VERSION ""

NS_ :

BS_:

BU_: XXX

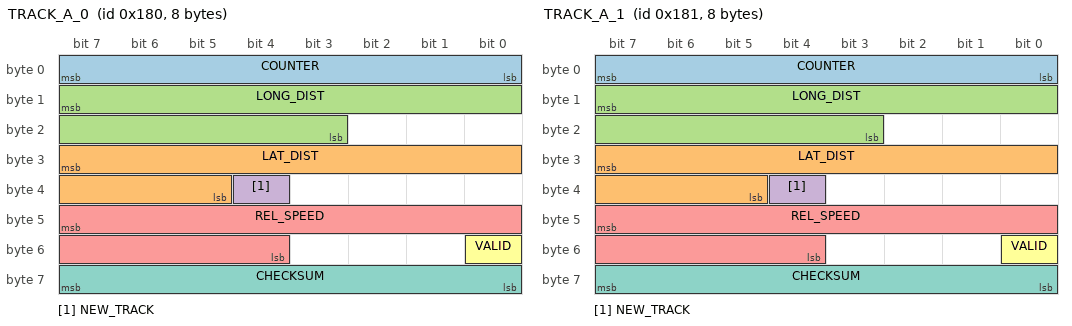
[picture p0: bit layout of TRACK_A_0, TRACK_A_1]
BO_ 384 TRACK_A_0: 8 XXX
 SG_ COUNTER : 7|8@0+ (1,0) [0|255] "" XXX
 SG_ LAT_DIST : 31|11@0- (0.04,0) [-50|50] "m" XXX
 SG_ LONG_DIST : 15|13@0+ (0.04,0) [0|300] "m" XXX
 SG_ NEW_TRACK : 36|1@0+ (1,0) [0|1] "" XXX
 SG_ REL_SPEED : 47|12@0- (0.025,0) [-100|100] "m/s" XXX
 SG_ VALID : 48|1@0+ (1,0) [0|1] "" XXX
 SG_ CHECKSUM : 63|8@0+ (1,0) [0|255] "" XXX

BO_ 385 TRACK_A_1: 8 XXX
 SG_ COUNTER : 7|8@0+ (1,0) [0|255] "" XXX
 SG_ LAT_DIST : 31|11@0- (0.04,0) [-50|50] "m" XXX
 SG_ LONG_DIST : 15|13@0+ (0.04,0) [0|300] "m" XXX
 SG_ NEW_TRACK : 36|1@0+ (1,0) [0|1] "" XXX
 SG_ REL_SPEED : 47|12@0- (0.025,0) [-100|100] "m/s" XXX
 SG_ VALID : 48|1@0+ (1,0) [0|1] "" XXX
 SG_ CHECKSUM : 63|8@0+ (1,0) [0|255] "" XXX

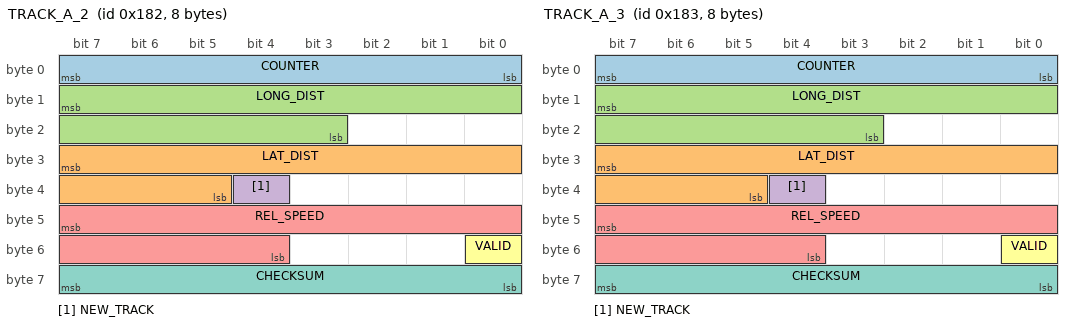
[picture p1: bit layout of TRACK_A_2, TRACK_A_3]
BO_ 386 TRACK_A_2: 8 XXX
 SG_ COUNTER : 7|8@0+ (1,0) [0|255] "" XXX
 SG_ LAT_DIST : 31|11@0- (0.04,0) [-50|50] "m" XXX
 SG_ LONG_DIST : 15|13@0+ (0.04,0) [0|300] "m" XXX
 SG_ NEW_TRACK : 36|1@0+ (1,0) [0|1] "" XXX
 SG_ REL_SPEED : 47|12@0- (0.025,0) [-100|100] "m/s" XXX
 SG_ VALID : 48|1@0+ (1,0) [0|1] "" XXX
 SG_ CHECKSUM : 63|8@0+ (1,0) [0|255] "" XXX

BO_ 387 TRACK_A_3: 8 XXX
 SG_ COUNTER : 7|8@0+ (1,0) [0|255] "" XXX
 SG_ LAT_DIST : 31|11@0- (0.04,0) [-50|50] "m" XXX
 SG_ LONG_DIST : 15|13@0+ (0.04,0) [0|300] "m" XXX
 SG_ NEW_TRACK : 36|1@0+ (1,0) [0|1] "" XXX
 SG_ REL_SPEED : 47|12@0- (0.025,0) [-100|100] "m/s" XXX
 SG_ VALID : 48|1@0+ (1,0) [0|1] "" XXX
 SG_ CHECKSUM : 63|8@0+ (1,0) [0|255] "" XXX

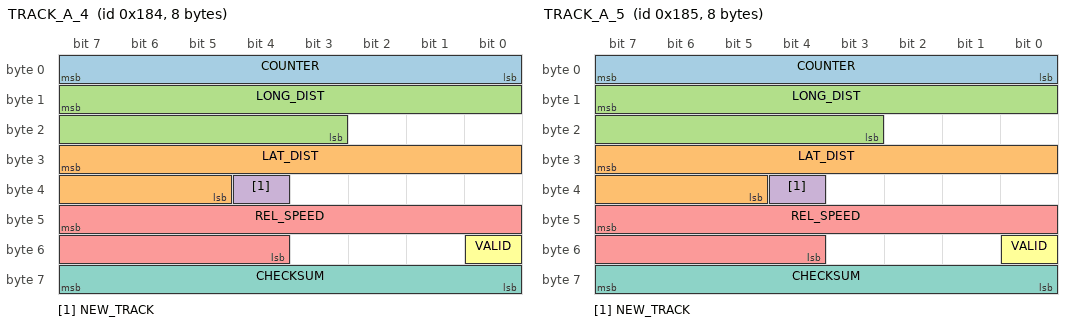
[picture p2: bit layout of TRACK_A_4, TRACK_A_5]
BO_ 388 TRACK_A_4: 8 XXX
 SG_ COUNTER : 7|8@0+ (1,0) [0|255] "" XXX
 SG_ LAT_DIST : 31|11@0- (0.04,0) [-50|50] "m" XXX
 SG_ LONG_DIST : 15|13@0+ (0.04,0) [0|300] "m" XXX
 SG_ NEW_TRACK : 36|1@0+ (1,0) [0|1] "" XXX
 SG_ REL_SPEED : 47|12@0- (0.025,0) [-100|100] "m/s" XXX
 SG_ VALID : 48|1@0+ (1,0) [0|1] "" XXX
 SG_ CHECKSUM : 63|8@0+ (1,0) [0|255] "" XXX

BO_ 389 TRACK_A_5: 8 XXX
 SG_ COUNTER : 7|8@0+ (1,0) [0|255] "" XXX
 SG_ LAT_DIST : 31|11@0- (0.04,0) [-50|50] "m" XXX
 SG_ LONG_DIST : 15|13@0+ (0.04,0) [0|300] "m" XXX
 SG_ NEW_TRACK : 36|1@0+ (1,0) [0|1] "" XXX
 SG_ REL_SPEED : 47|12@0- (0.025,0) [-100|100] "m/s" XXX
 SG_ VALID : 48|1@0+ (1,0) [0|1] "" XXX
 SG_ CHECKSUM : 63|8@0+ (1,0) [0|255] "" XXX

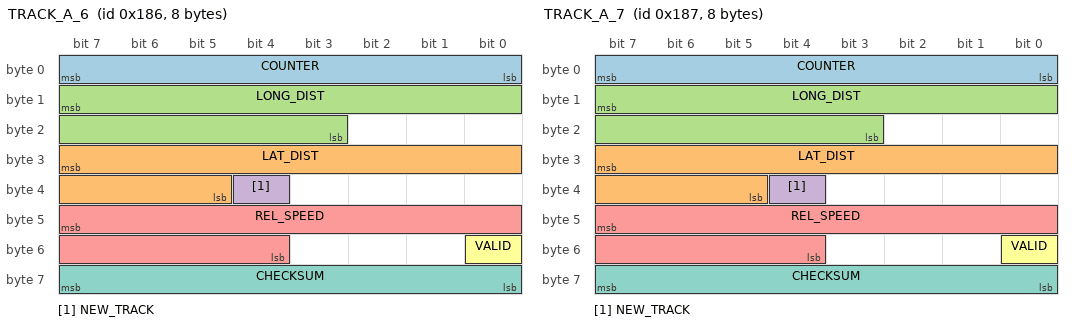
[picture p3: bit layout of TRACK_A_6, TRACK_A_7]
BO_ 390 TRACK_A_6: 8 XXX
 SG_ COUNTER : 7|8@0+ (1,0) [0|255] "" XXX
 SG_ LAT_DIST : 31|11@0- (0.04,0) [-50|50] "m" XXX
 SG_ LONG_DIST : 15|13@0+ (0.04,0) [0|300] "m" XXX
 SG_ NEW_TRACK : 36|1@0+ (1,0) [0|1] "" XXX
 SG_ REL_SPEED : 47|12@0- (0.025,0) [-100|100] "m/s" XXX
 SG_ VALID : 48|1@0+ (1,0) [0|1] "" XXX
 SG_ CHECKSUM : 63|8@0+ (1,0) [0|255] "" XXX

BO_ 391 TRACK_A_7: 8 XXX
 SG_ COUNTER : 7|8@0+ (1,0) [0|255] "" XXX
 SG_ LAT_DIST : 31|11@0- (0.04,0) [-50|50] "m" XXX
 SG_ LONG_DIST : 15|13@0+ (0.04,0) [0|300] "m" XXX
 SG_ NEW_TRACK : 36|1@0+ (1,0) [0|1] "" XXX
 SG_ REL_SPEED : 47|12@0- (0.025,0) [-100|100] "m/s" XXX
 SG_ VALID : 48|1@0+ (1,0) [0|1] "" XXX
 SG_ CHECKSUM : 63|8@0+ (1,0) [0|255] "" XXX

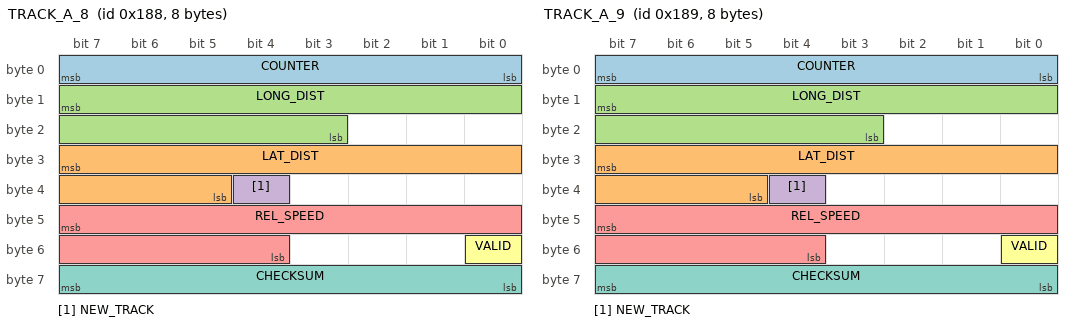
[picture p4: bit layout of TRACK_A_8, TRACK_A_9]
BO_ 392 TRACK_A_8: 8 XXX
 SG_ COUNTER : 7|8@0+ (1,0) [0|255] "" XXX
 SG_ LAT_DIST : 31|11@0- (0.04,0) [-50|50] "m" XXX
 SG_ LONG_DIST : 15|13@0+ (0.04,0) [0|300] "m" XXX
 SG_ NEW_TRACK : 36|1@0+ (1,0) [0|1] "" XXX
 SG_ REL_SPEED : 47|12@0- (0.025,0) [-100|100] "m/s" XXX
 SG_ VALID : 48|1@0+ (1,0) [0|1] "" XXX
 SG_ CHECKSUM : 63|8@0+ (1,0) [0|255] "" XXX

BO_ 393 TRACK_A_9: 8 XXX
 SG_ COUNTER : 7|8@0+ (1,0) [0|255] "" XXX
 SG_ LAT_DIST : 31|11@0- (0.04,0) [-50|50] "m" XXX
 SG_ LONG_DIST : 15|13@0+ (0.04,0) [0|300] "m" XXX
 SG_ NEW_TRACK : 36|1@0+ (1,0) [0|1] "" XXX
 SG_ REL_SPEED : 47|12@0- (0.025,0) [-100|100] "m/s" XXX
 SG_ VALID : 48|1@0+ (1,0) [0|1] "" XXX
 SG_ CHECKSUM : 63|8@0+ (1,0) [0|255] "" XXX

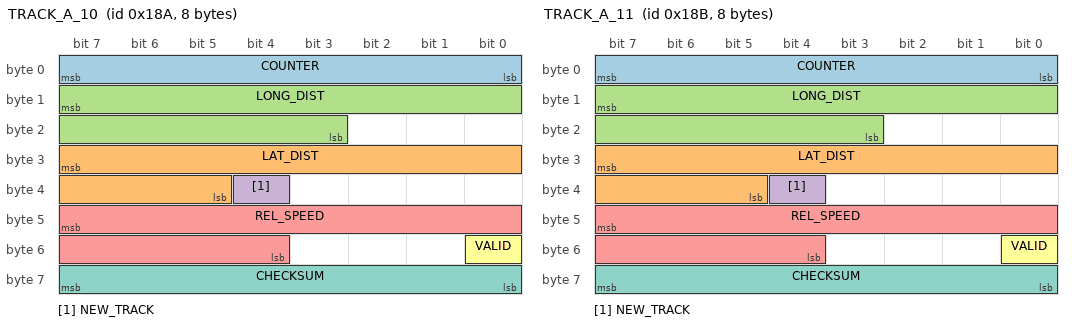
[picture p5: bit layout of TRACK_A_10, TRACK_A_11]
BO_ 394 TRACK_A_10: 8 XXX
 SG_ COUNTER : 7|8@0+ (1,0) [0|255] "" XXX
 SG_ LAT_DIST : 31|11@0- (0.04,0) [-50|50] "m" XXX
 SG_ LONG_DIST : 15|13@0+ (0.04,0) [0|300] "m" XXX
 SG_ NEW_TRACK : 36|1@0+ (1,0) [0|1] "" XXX
 SG_ REL_SPEED : 47|12@0- (0.025,0) [-100|100] "m/s" XXX
 SG_ VALID : 48|1@0+ (1,0) [0|1] "" XXX
 SG_ CHECKSUM : 63|8@0+ (1,0) [0|255] "" XXX

BO_ 395 TRACK_A_11: 8 XXX
 SG_ COUNTER : 7|8@0+ (1,0) [0|255] "" XXX
 SG_ LAT_DIST : 31|11@0- (0.04,0) [-50|50] "m" XXX
 SG_ LONG_DIST : 15|13@0+ (0.04,0) [0|300] "m" XXX
 SG_ NEW_TRACK : 36|1@0+ (1,0) [0|1] "" XXX
 SG_ REL_SPEED : 47|12@0- (0.025,0) [-100|100] "m/s" XXX
 SG_ VALID : 48|1@0+ (1,0) [0|1] "" XXX
 SG_ CHECKSUM : 63|8@0+ (1,0) [0|255] "" XXX

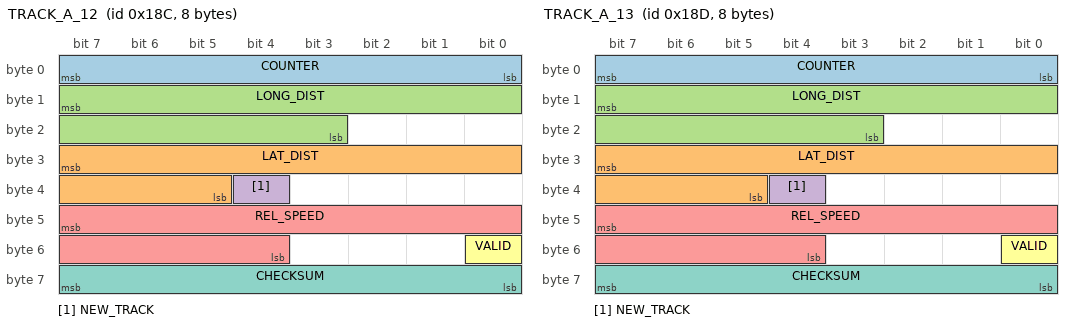
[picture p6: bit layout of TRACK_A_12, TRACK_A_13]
BO_ 396 TRACK_A_12: 8 XXX
 SG_ COUNTER : 7|8@0+ (1,0) [0|255] "" XXX
 SG_ LAT_DIST : 31|11@0- (0.04,0) [-50|50] "m" XXX
 SG_ LONG_DIST : 15|13@0+ (0.04,0) [0|300] "m" XXX
 SG_ NEW_TRACK : 36|1@0+ (1,0) [0|1] "" XXX
 SG_ REL_SPEED : 47|12@0- (0.025,0) [-100|100] "m/s" XXX
 SG_ VALID : 48|1@0+ (1,0) [0|1] "" XXX
 SG_ CHECKSUM : 63|8@0+ (1,0) [0|255] "" XXX

BO_ 397 TRACK_A_13: 8 XXX
 SG_ COUNTER : 7|8@0+ (1,0) [0|255] "" XXX
 SG_ LAT_DIST : 31|11@0- (0.04,0) [-50|50] "m" XXX
 SG_ LONG_DIST : 15|13@0+ (0.04,0) [0|300] "m" XXX
 SG_ NEW_TRACK : 36|1@0+ (1,0) [0|1] "" XXX
 SG_ REL_SPEED : 47|12@0- (0.025,0) [-100|100] "m/s" XXX
 SG_ VALID : 48|1@0+ (1,0) [0|1] "" XXX
 SG_ CHECKSUM : 63|8@0+ (1,0) [0|255] "" XXX

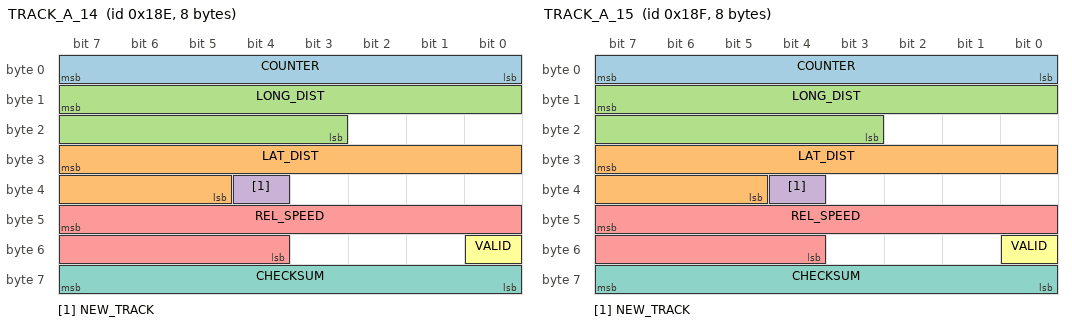
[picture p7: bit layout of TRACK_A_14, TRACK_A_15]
BO_ 398 TRACK_A_14: 8 XXX
 SG_ COUNTER : 7|8@0+ (1,0) [0|255] "" XXX
 SG_ LAT_DIST : 31|11@0- (0.04,0) [-50|50] "m" XXX
 SG_ LONG_DIST : 15|13@0+ (0.04,0) [0|300] "m" XXX
 SG_ NEW_TRACK : 36|1@0+ (1,0) [0|1] "" XXX
 SG_ REL_SPEED : 47|12@0- (0.025,0) [-100|100] "m/s" XXX
 SG_ VALID : 48|1@0+ (1,0) [0|1] "" XXX
 SG_ CHECKSUM : 63|8@0+ (1,0) [0|255] "" XXX

BO_ 399 TRACK_A_15: 8 XXX
 SG_ COUNTER : 7|8@0+ (1,0) [0|255] "" XXX
 SG_ LAT_DIST : 31|11@0- (0.04,0) [-50|50] "m" XXX
 SG_ LONG_DIST : 15|13@0+ (0.04,0) [0|300] "m" XXX
 SG_ NEW_TRACK : 36|1@0+ (1,0) [0|1] "" XXX
 SG_ REL_SPEED : 47|12@0- (0.025,0) [-100|100] "m/s" XXX
 SG_ VALID : 48|1@0+ (1,0) [0|1] "" XXX
 SG_ CHECKSUM : 63|8@0+ (1,0) [0|255] "" XXX

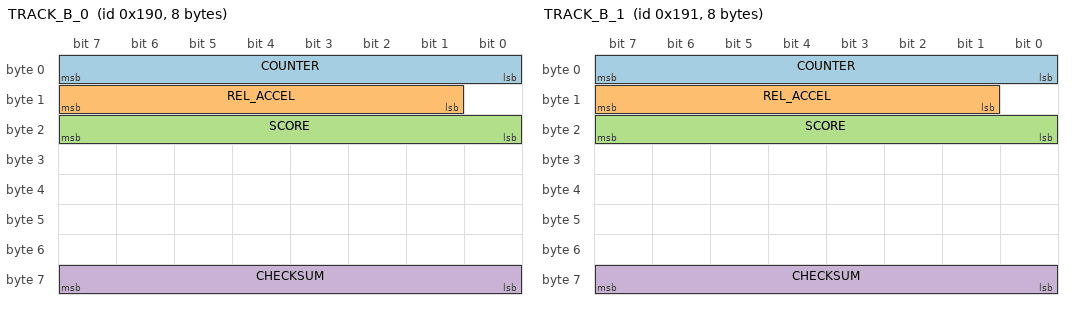
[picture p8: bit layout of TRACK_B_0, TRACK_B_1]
BO_ 400 TRACK_B_0: 8 XXX
 SG_ COUNTER : 7|8@0+ (1,0) [0|255] "" XXX
 SG_ REL_ACCEL : 15|7@0- (1,0) [-64|63] "" XXX
 SG_ SCORE : 23|8@0+ (1,0) [0|100] "" XXX
 SG_ CHECKSUM : 63|8@0+ (1,0) [0|255] "" XXX

BO_ 401 TRACK_B_1: 8 XXX
 SG_ COUNTER : 7|8@0+ (1,0) [0|255] "" XXX
 SG_ REL_ACCEL : 15|7@0- (1,0) [-64|63] "" XXX
 SG_ SCORE : 23|8@0+ (1,0) [0|100] "" XXX
 SG_ CHECKSUM : 63|8@0+ (1,0) [0|255] "" XXX

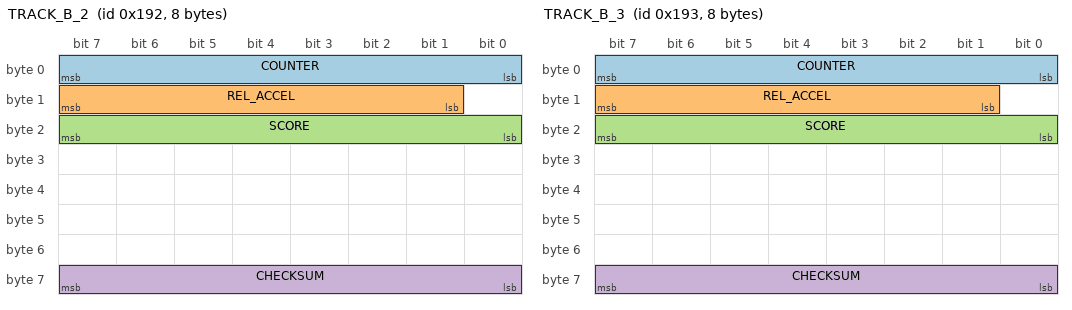
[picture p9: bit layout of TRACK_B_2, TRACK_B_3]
BO_ 402 TRACK_B_2: 8 XXX
 SG_ COUNTER : 7|8@0+ (1,0) [0|255] "" XXX
 SG_ REL_ACCEL : 15|7@0- (1,0) [-64|63] "" XXX
 SG_ SCORE : 23|8@0+ (1,0) [0|100] "" XXX
 SG_ CHECKSUM : 63|8@0+ (1,0) [0|255] "" XXX

BO_ 403 TRACK_B_3: 8 XXX
 SG_ COUNTER : 7|8@0+ (1,0) [0|255] "" XXX
 SG_ REL_ACCEL : 15|7@0- (1,0) [-64|63] "" XXX
 SG_ SCORE : 23|8@0+ (1,0) [0|100] "" XXX
 SG_ CHECKSUM : 63|8@0+ (1,0) [0|255] "" XXX

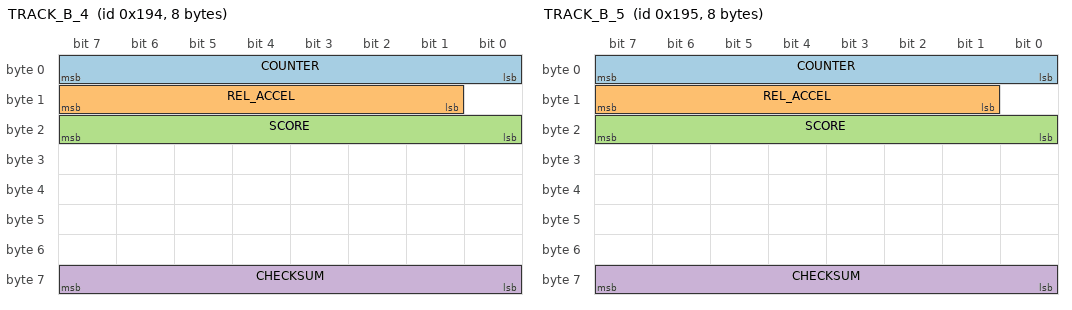
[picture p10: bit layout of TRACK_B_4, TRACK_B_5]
BO_ 404 TRACK_B_4: 8 XXX
 SG_ COUNTER : 7|8@0+ (1,0) [0|255] "" XXX
 SG_ REL_ACCEL : 15|7@0- (1,0) [-64|63] "" XXX
 SG_ SCORE : 23|8@0+ (1,0) [0|100] "" XXX
 SG_ CHECKSUM : 63|8@0+ (1,0) [0|255] "" XXX

BO_ 405 TRACK_B_5: 8 XXX
 SG_ COUNTER : 7|8@0+ (1,0) [0|255] "" XXX
 SG_ REL_ACCEL : 15|7@0- (1,0) [-64|63] "" XXX
 SG_ SCORE : 23|8@0+ (1,0) [0|100] "" XXX
 SG_ CHECKSUM : 63|8@0+ (1,0) [0|255] "" XXX

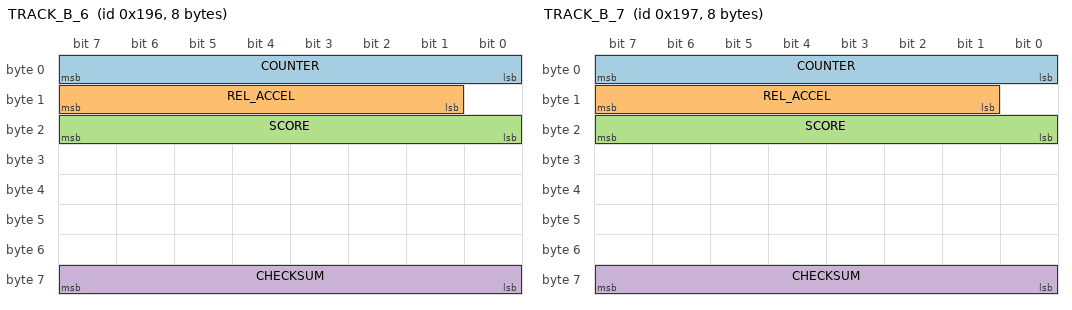
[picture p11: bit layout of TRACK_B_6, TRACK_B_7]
BO_ 406 TRACK_B_6: 8 XXX
 SG_ COUNTER : 7|8@0+ (1,0) [0|255] "" XXX
 SG_ REL_ACCEL : 15|7@0- (1,0) [-64|63] "" XXX
 SG_ SCORE : 23|8@0+ (1,0) [0|100] "" XXX
 SG_ CHECKSUM : 63|8@0+ (1,0) [0|255] "" XXX

BO_ 407 TRACK_B_7: 8 XXX
 SG_ COUNTER : 7|8@0+ (1,0) [0|255] "" XXX
 SG_ REL_ACCEL : 15|7@0- (1,0) [-64|63] "" XXX
 SG_ SCORE : 23|8@0+ (1,0) [0|100] "" XXX
 SG_ CHECKSUM : 63|8@0+ (1,0) [0|255] "" XXX

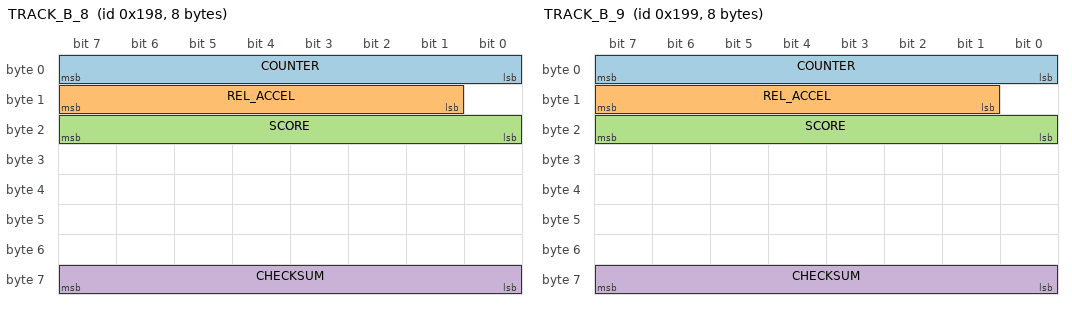
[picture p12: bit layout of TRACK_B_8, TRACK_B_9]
BO_ 408 TRACK_B_8: 8 XXX
 SG_ COUNTER : 7|8@0+ (1,0) [0|255] "" XXX
 SG_ REL_ACCEL : 15|7@0- (1,0) [-64|63] "" XXX
 SG_ SCORE : 23|8@0+ (1,0) [0|100] "" XXX
 SG_ CHECKSUM : 63|8@0+ (1,0) [0|255] "" XXX

BO_ 409 TRACK_B_9: 8 XXX
 SG_ COUNTER : 7|8@0+ (1,0) [0|255] "" XXX
 SG_ REL_ACCEL : 15|7@0- (1,0) [-64|63] "" XXX
 SG_ SCORE : 23|8@0+ (1,0) [0|100] "" XXX
 SG_ CHECKSUM : 63|8@0+ (1,0) [0|255] "" XXX

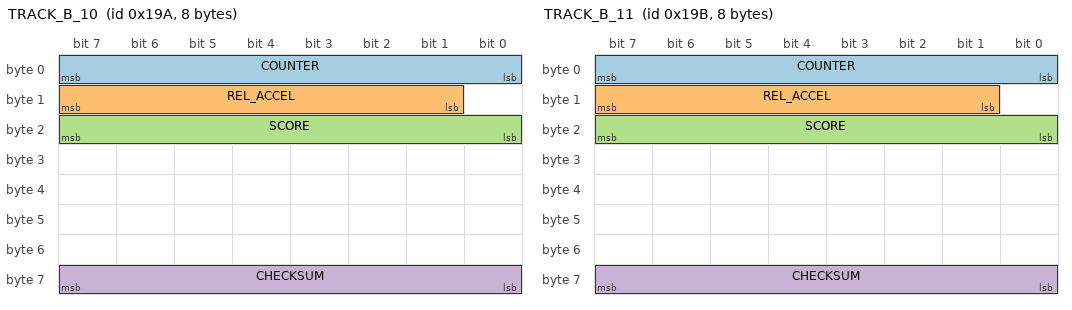
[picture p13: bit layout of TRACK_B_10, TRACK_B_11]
BO_ 410 TRACK_B_10: 8 XXX
 SG_ COUNTER : 7|8@0+ (1,0) [0|255] "" XXX
 SG_ REL_ACCEL : 15|7@0- (1,0) [-64|63] "" XXX
 SG_ SCORE : 23|8@0+ (1,0) [0|100] "" XXX
 SG_ CHECKSUM : 63|8@0+ (1,0) [0|255] "" XXX

BO_ 411 TRACK_B_11: 8 XXX
 SG_ COUNTER : 7|8@0+ (1,0) [0|255] "" XXX
 SG_ REL_ACCEL : 15|7@0- (1,0) [-64|63] "" XXX
 SG_ SCORE : 23|8@0+ (1,0) [0|100] "" XXX
 SG_ CHECKSUM : 63|8@0+ (1,0) [0|255] "" XXX

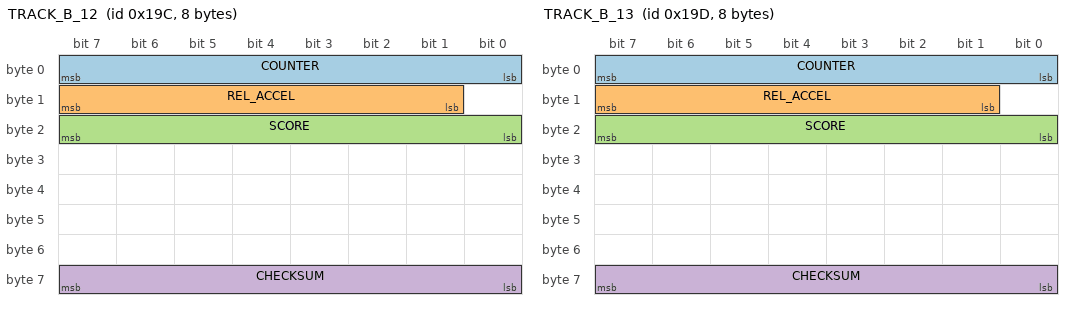
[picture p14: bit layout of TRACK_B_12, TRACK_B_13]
BO_ 412 TRACK_B_12: 8 XXX
 SG_ COUNTER : 7|8@0+ (1,0) [0|255] "" XXX
 SG_ REL_ACCEL : 15|7@0- (1,0) [-64|63] "" XXX
 SG_ SCORE : 23|8@0+ (1,0) [0|100] "" XXX
 SG_ CHECKSUM : 63|8@0+ (1,0) [0|255] "" XXX

BO_ 413 TRACK_B_13: 8 XXX
 SG_ COUNTER : 7|8@0+ (1,0) [0|255] "" XXX
 SG_ REL_ACCEL : 15|7@0- (1,0) [-64|63] "" XXX
 SG_ SCORE : 23|8@0+ (1,0) [0|100] "" XXX
 SG_ CHECKSUM : 63|8@0+ (1,0) [0|255] "" XXX

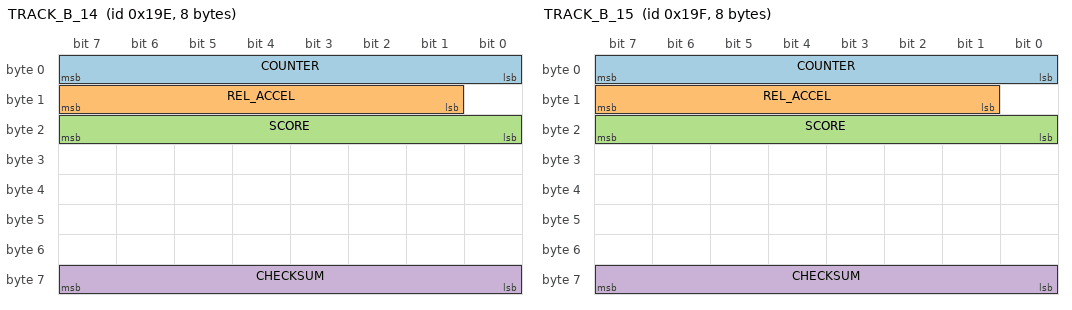
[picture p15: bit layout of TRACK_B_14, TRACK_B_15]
BO_ 414 TRACK_B_14: 8 XXX
 SG_ COUNTER : 7|8@0+ (1,0) [0|255] "" XXX
 SG_ REL_ACCEL : 15|7@0- (1,0) [-64|63] "" XXX
 SG_ SCORE : 23|8@0+ (1,0) [0|100] "" XXX
 SG_ CHECKSUM : 63|8@0+ (1,0) [0|255] "" XXX

BO_ 415 TRACK_B_15: 8 XXX
 SG_ COUNTER : 7|8@0+ (1,0) [0|255] "" XXX
 SG_ REL_ACCEL : 15|7@0- (1,0) [-64|63] "" XXX
 SG_ SCORE : 23|8@0+ (1,0) [0|100] "" XXX
 SG_ CHECKSUM : 63|8@0+ (1,0) [0|255] "" XXX

BO_ 576 NEW_MSG_1: 8 XXX
 SG_ NEW_SIGNAL_1 : 15|7@0+ (1,0) [0|127] "" XXX
 SG_ NEW_SIGNAL_2 : 23|8@0+ (1,0) [0|255] "" XXX

BO_ 577 NEW_MSG_2: 8 XXX
 SG_ NEW_SIGNAL_1 : 15|7@0+ (1,0) [0|127] "" XXX
 SG_ NEW_SIGNAL_2 : 23|8@0+ (1,0) [0|255] "" XXX

BO_ 578 NEW_MSG_3: 8 XXX
 SG_ NEW_SIGNAL_1 : 15|7@0+ (1,0) [0|127] "" XXX
 SG_ NEW_SIGNAL_2 : 23|8@0+ (1,0) [0|255] "" XXX

BO_ 579 NEW_MSG_4: 8 XXX
 SG_ NEW_SIGNAL_1 : 15|7@0+ (1,0) [0|127] "" XXX
 SG_ NEW_SIGNAL_2 : 23|8@0+ (1,0) [0|255] "" XXX

BO_ 580 NEW_MSG_5: 8 XXX
 SG_ NEW_SIGNAL_1 : 15|7@0+ (1,0) [0|127] "" XXX
 SG_ NEW_SIGNAL_2 : 23|8@0+ (1,0) [0|255] "" XXX

BO_ 581 NEW_MSG_6: 8 XXX
 SG_ NEW_SIGNAL_1 : 15|7@0+ (1,0) [0|127] "" XXX
 SG_ NEW_SIGNAL_2 : 23|8@0+ (1,0) [0|255] "" XXX

BO_ 582 NEW_MSG_7: 8 XXX
 SG_ NEW_SIGNAL_1 : 15|7@0+ (1,0) [0|127] "" XXX
 SG_ NEW_SIGNAL_2 : 23|8@0+ (1,0) [0|255] "" XXX

BO_ 583 NEW_MSG_8: 8 XXX
 SG_ NEW_SIGNAL_1 : 15|7@0+ (1,0) [0|127] "" XXX
 SG_ NEW_SIGNAL_2 : 23|8@0+ (1,0) [0|255] "" XXX

BO_ 584 NEW_MSG_9: 8 XXX
 SG_ NEW_SIGNAL_1 : 15|7@0+ (1,0) [0|127] "" XXX
 SG_ NEW_SIGNAL_2 : 23|8@0+ (1,0) [0|255] "" XXX
